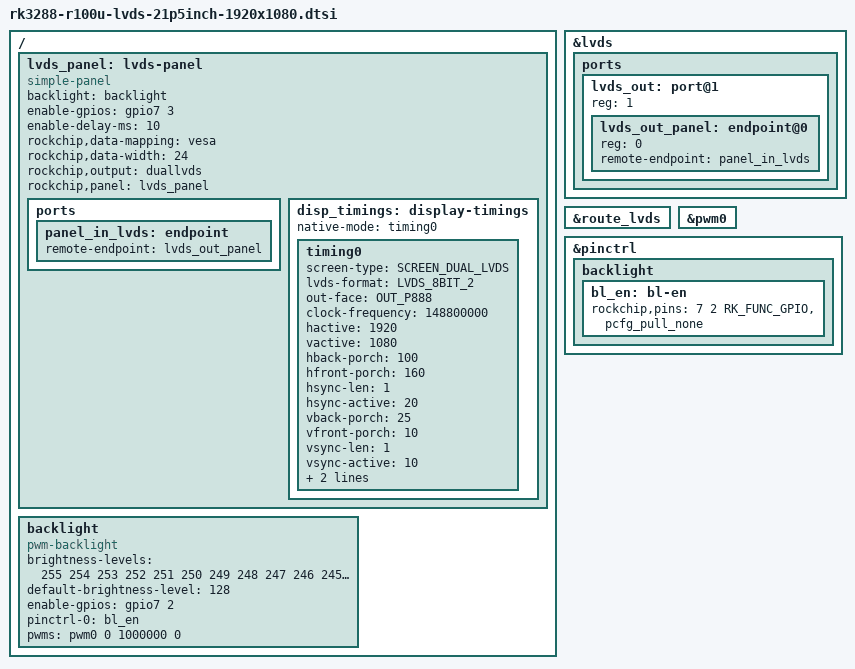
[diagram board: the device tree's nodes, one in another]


/ {
    /** lvds -------------------------------------------------------------*/
    lvds_panel: lvds-panel {
		status = "okay";

	    compatible ="simple-panel";
        backlight = <&backlight>;
        // bus-format = <MEDIA_BUS_FMT_RGB888_2X18>;
        enable-gpios = <&gpio7 3 GPIO_ACTIVE_HIGH>;
        enable-delay-ms = <10>;
        // power-supply = <&vcc_lcd>;
        // pinctrl-0 = <&lvds_en>;
        // rockchip,data-mapping = "jeida";     // 花屏
        rockchip,data-mapping = "vesa";
        rockchip,data-width = <24>;
        rockchip,output = "duallvds";
        rockchip,panel = <&lvds_panel>;
		ports {
			panel_in_lvds: endpoint {
				remote-endpoint = <&lvds_out_panel>;
			};
		};
        
        disp_timings: display-timings {
        native-mode = <&timing0>;
            timing0: timing0 {
                screen-type = <SCREEN_DUAL_LVDS>;
                // lvds-format = <LVDS_8BIT_1>;     // too much noise
                lvds-format = <LVDS_8BIT_2>;
                out-face    = <OUT_P888>;
                // clock-frequency = <148600000>;
                clock-frequency = <148800000>;
                hactive = <1920>;             // Horizontal display area thd 1024       DCLK            
                vactive = <1080>;             // Vertical display area tvd   600        H               
                hback-porch = <100>;           // HS Width +Back Porch   160  160   160  DCLK (Thw+ thbp)
                hfront-porch = <160>;          // HS front porch thfp    16   160   216  DCLK            
                hsync-len = <1>;             // HS Pulse Width thw     1     -    140  DCLK    
                hsync-active = <20>;
                vback-porch = <25>;            // VS front porch tvfp    1    12    127  H               
                vfront-porch = <10>;           // VS Width+Back Porch    23   23    23   H (Tvw+ tvbp)   
                vsync-len = <1>;              // VS Pulse Width tvw     1     -     20  H               
                vsync-active = <10>;
                de-active = <0>;
                pixelclk-active = <0>;
                
                // clock-frequency = <148600000>;
                // hactive = <1920>;             /* Horizontal display area thd 1024       DCLK            */
                // vactive = <1080>;             /* Vertical display area tvd   600        H               */
                // hback-porch = <48>;           /* HS Width +Back Porch   160  160   160  DCLK (Thw+ thbp)*/
                // hfront-porch = <48>;          /* HS front porch thfp    16   160   216  DCLK            */
                // vback-porch = <8>;            /* VS front porch tvfp    1    12    127  H               */
                // vfront-porch = <8>;       /* VS Width+Back Porch    23   23    23   H (Tvw+ tvbp)   */
                // hsync-len = <40>;             /* HS Pulse Width thw     1     -    140  DCLK            */
                // vsync-len = <4>;              /* VS Pulse Width tvw     1     -     20  H               */
                // hsync-active = <0>;
                // vsync-active = <0>;
                // de-active = <0>;
                // pixelclk-active = <0>;
            };
        };
    };
    
    backlight: backlight {
    compatible = "pwm-backlight";
    brightness-levels = 
        <
        255 254 253 252 251 250 249 248 247 246 
        245 244 243 242 241 240 239 238 237 236 
        235 234 233 232 231 230 229 228 227 226 
        225 224 223 222 221 220 219 218 217 216 
        215 214 213 212 211 210 209 208 207 206 
        205 204 203 202 201 200 199 198 197 196 
        195 194 193 192 191 190 189 188 187 186 
        185 184 183 182 181 180 179 178 177 176 
        175 174 173 172 171 170 169 168 167 166 
        165 164 163 162 161 160 159 158 157 156 
        155 154 153 152 151 150 149 148 147 146 
        145 144 143 142 141 140 139 138 137 136
        135 134 133 132 131 130 129 128 127 126 
        125 124 123 122 121 120 119 118 117 116 
        115 114 113 112 111 110 109 108 107 106 
        105 104 103 102 101 100 99  98  97  96 
        95  94  93  92  91  90  89  88  87  86 
        85  84  83  82  81  80  79  78  77  76 
        75  74  73  72  71  70  69  68  67  66 
        65  64  63  62  61  60  59  58  57  56 
        55  54  53  52  51  50  49  48  47  46 
        45  44  43  42  41  40  39  38  37  36 
        35  34  33  32  31  30  29  28  27  26 
        25  24  23  22  21  20  19  18  17  16 
        15  14  13  12  11  10  9   8   7   6 
        5   4   3   2   1   0>;

        default-brightness-level = <128>;
        enable-gpios = <&gpio7 2 GPIO_ACTIVE_HIGH>;
        pinctrl-names = "default";
        pinctrl-0 = <&bl_en>;
        pwms = <&pwm0 0 1000000 0>;
    };
};

&lvds {
	status = "okay";
	ports {
		lvds_out: port@1 {
			reg = <1>;
			#address-cells = <1>;
			#size-cells = <0>;

			lvds_out_panel: endpoint@0 {
				reg = <0>;
				remote-endpoint = <&panel_in_lvds>;
			};
		};
	};
};

// /** set display to lvds ---------------------*/
&route_lvds {
    status = "okay";
};

&pwm0 {
	status = "okay";
};

&pinctrl {
	backlight {
		bl_en: bl-en {
			rockchip,pins = <7 2 RK_FUNC_GPIO &pcfg_pull_none>;
		};
	};
};
